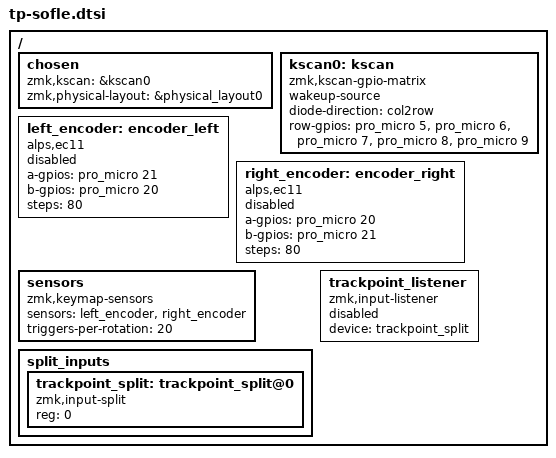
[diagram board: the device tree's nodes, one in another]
/*
 * Copyright (c) 2020 Pete Johanson, Ryan Cross
 *
 * SPDX-License-Identifier: MIT
 */

#include <dt-bindings/zmk/matrix_transform.h>
#include <physical_layouts.dtsi>
#include "tp-sofle-layouts.dtsi"

/ {
    chosen {
        zmk,kscan = &kscan0;
        zmk,physical-layout = &physical_layout0;
    };

    kscan0: kscan {
        compatible = "zmk,kscan-gpio-matrix";
        wakeup-source;

        diode-direction = "col2row";
        row-gpios
            = <&pro_micro 5 (GPIO_ACTIVE_HIGH | GPIO_PULL_DOWN)>
            , <&pro_micro 6 (GPIO_ACTIVE_HIGH | GPIO_PULL_DOWN)>
            , <&pro_micro 7 (GPIO_ACTIVE_HIGH | GPIO_PULL_DOWN)>
            , <&pro_micro 8 (GPIO_ACTIVE_HIGH | GPIO_PULL_DOWN)>
            , <&pro_micro 9 (GPIO_ACTIVE_HIGH | GPIO_PULL_DOWN)>
            ;
    };

    left_encoder: encoder_left {
        compatible = "alps,ec11";
        a-gpios = <&pro_micro 21 (GPIO_ACTIVE_HIGH | GPIO_PULL_UP)>;
        b-gpios = <&pro_micro 20 (GPIO_ACTIVE_HIGH | GPIO_PULL_UP)>;
        steps = <80>;
        status = "disabled";
    };

    right_encoder: encoder_right {
        compatible = "alps,ec11";
        a-gpios = <&pro_micro 20 (GPIO_ACTIVE_HIGH | GPIO_PULL_UP)>;
        b-gpios = <&pro_micro 21 (GPIO_ACTIVE_HIGH | GPIO_PULL_UP)>;
        steps = <80>;
        status = "disabled";
    };

    sensors: sensors {
        compatible = "zmk,keymap-sensors";
        sensors = <&left_encoder &right_encoder>;
        triggers-per-rotation = <20>;
    };
};

/ {
    split_inputs {
        #address-cells = <1>;
        #size-cells = <0>;

        trackpoint_split: trackpoint_split@0 {
            compatible = "zmk,input-split";
            reg = <0>;
        };
    };

    trackpoint_listener: trackpoint_listener {
        compatible = "zmk,input-listener";
        status = "disabled";
        device = <&trackpoint_split>;
    };
};
